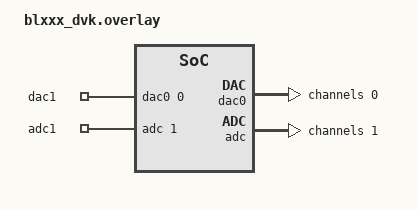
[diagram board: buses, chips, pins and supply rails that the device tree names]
/*
 * Copyright 2021 Laird Connectivity
 *
 * SPDX-License-Identifier: Apache-2.0
 */

/ {
	zephyr,user {
		io-channels = <&dac0 0 &adc 1>;
		io-channel-names = "dac1", "adc1";
	};
};

&dac0 {
	status = "okay";

	#address-cells = <1>;
	#size-cells = <0>;

	channel@0 {
		reg = <0>;
		zephyr,resolution = <12>;
	};
};

&adc {
	status = "okay";

	#address-cells = <1>;
	#size-cells = <0>;

	channel@1 {
		reg = <1>;
		zephyr,gain = "ADC_GAIN_1_4";
		zephyr,reference = "ADC_REF_VDD_1_4";
		zephyr,resolution = <12>;
		zephyr,acquisition-time = <ADC_ACQ_TIME_DEFAULT>;
		zephyr,input-positive = <NRF_SAADC_AIN1>;
	};
};
